# STM32H7S register map
File version: 1.4
CPU: CM7 r0p1, little endian, MPU, FPU, 4 interrupt priority bits
Registers are 32-bit, read-write, reset 0x0 unless marked. A register's access mark holds for its fields unless they carry their own. Offsets are from the block's base; [hi:lo] are bit positions; {n}, {i} and the like mark numbered series; 'fields as' and 'values as' point back to an identical list.

## ECC_DIAG_D1 — RAMECC1 configuration controller
Base 0x52009000
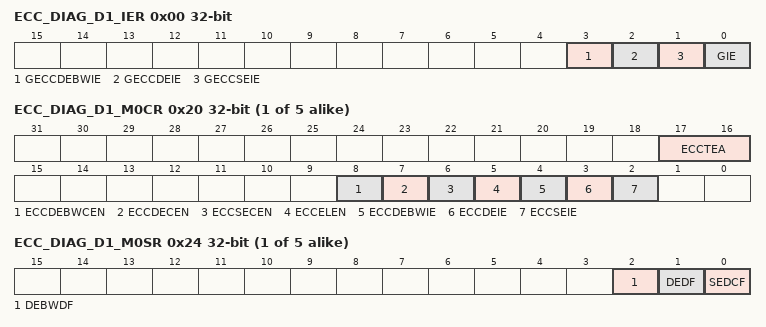
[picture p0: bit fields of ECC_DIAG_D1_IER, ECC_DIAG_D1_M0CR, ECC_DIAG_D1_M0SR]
0x00 ECC_DIAG_D1_IER — RAMECC interrupt enable register
  [3] GECCDEBWIE — Global ECC double error on byte write (BW) interrupt enable When GECCDEBWIE bit is set to 1, an interrupt is generated when an ECC double detection error occurs during a byte write operation to RAM (incomplete word write).
    0=no interrupt generated when an ECC double detection error occurs on byte write; 1=interrupt generated if an ECC double detection error occurs on byte write
  [2] GECCDEIE — Global ECC double error interrupt enable When GECCDEIE bit is set to 1, an interrupt is generated when an ECC double detection error occurs during a read operation from RAM.
    0=no interrupt generated when an ECC double detection error occurs; 1=interrupt generated if an ECC double detection error occurs
  [1] GECCSEIE — Global ECC single error interrupt enable When GECCSEIE bit is set to 1, an interrupt is generated when an ECC single error occurs during a read operation from RAM.
    0=no interrupt generated when an ECC single error occurs; 1=interrupt generated when an ECC single error occurs
  [0] GIE — Global interrupt enable When GIE bit is set to 1, an interrupt is generated when an enabled global ECC error (GECCDEBWIE, GECCDEIE or GECCSEIE) occurs.
    0=no interrupt generated when an ECC error occurs; 1=interrupt generated when an ECC error occurs
{0x20+0x20*i} ECC_DIAG_D1_M{i}CR (i=0..4) — RAMECC monitor {i} configuration register
  [17:16] ECCTEA — ECC Test ECC access
    0=inactive; 1=write and read access blocked on data memory; 2=write and read access blocked on ECC memory; 3=inactive
  [8] ECCDEBWCEN — ECC double error on byte write (BW) counter enable When ECCDEBWCEN bit is set to 1, the occurrence counter is incremented when an ECC double detection error occurs during a byte write operation to RAM.
    0=no counter increment when an ECC double detection error occurs on byte write; 1=counter increment when an ECC double detection error occurs on byte write
  [7] ECCDECEN — ECC double error counter enable When ECCDECEN bit is set to 1, the occurrence counter is incremented when an ECC double detection error occurs during a read operation from RAM.
    0=no counter increment when an ECC double detection error occurs; 1=counter increment when an ECC double detection error occurs
  [6] ECCSECEN — ECC single error counter enable When ECCSECEN bit is set to 1, the occurrence counter is incremented when an ECC single error occurs during a read operation from RAM.
    0=no counter increment when an ECC single error occurs; 1=counter increment when an ECC single error occurs
  [5] ECCELEN — ECC error latching enable When ECCELEN bit is set to 1, if an ECC error occurs (both for single error correction or double detection) during a read operation, the context (address, data and ECC code) that generated the error are latched to their respective registers.
    0=no error context preserved when an ECC error occurs; 1=error context preserved when an ECC error occurs
  [4] ECCDEBWIE — ECC double error on byte write (BW) interrupt enable When ECCDEBWIE bit is set to 1, monitor x generates an interrupt when an ECC double detection error occurs during a byte write operation to RAM.
    values as ECC_DIAG_D1_IER.GECCDEBWIE
  [3] ECCDEIE — ECC double error interrupt enable When ECCDEIE bit is set to 1, monitor x generates an interrupt when an ECC double detection error occurs during a read operation from RAM.
    values as ECC_DIAG_D1_IER.GECCDEIE
  [2] ECCSEIE — ECC single error interrupt enable When ECCSEIE bit is set to 1, monitor x generates an interrupt when an ECC single error occurs during a read operation from RAM.
    values as ECC_DIAG_D1_IER.GECCSEIE
{0x24+0x20*i} ECC_DIAG_D1_M{i}SR (i=0..4) — RAMECC monitor {i} status register
  [2] DEBWDF — ECC double error on byte write (BW) detected flag This bit is set by hardware. It is cleared by software by writing a 0
    0=no error detected; 1=error detected
  [1] DEDF — ECC double error detected flag This bit is set by hardware. It is cleared by software by writing a 0
    0=no error detected; 1=error detected
  [0] SEDCF — ECC single error detected and corrected flag This bit is set by hardware. It is cleared by software by writing a 0
    0=no error detected and corrected; 1=error detected and corrected
{0x28+0x20*i} ECC_DIAG_D1_M{i}FAR ro (i=0..4) — RAMECC monitor {i} failing address register
  [31:0] FADD — ECC error failing address When an ECC error occurs the FADD bit field contains the address that generated the ECC error.
{0x2C+0x20*i} ECC_DIAG_D1_M{i}FDRL ro (i=0..4) — RAMECC monitor {i} failing data low register
  [31:0] FDATAL — Failing data low When an ECC error occurs the FDATAL bit field contains the LSB part of the data that generated the error. For 32-bit word SRAM, this bit field contains the full memory word that generated the error.
{0x30+0x20*i} ECC_DIAG_D1_M{i}FDRH ro (i=0..4) — RAMECC monitor {i} failing data high register
  [31:0] FDATAH — Failing data high (64-bit memory) When an ECC error occurs the FDATAH bit field contains the MSB part of the data that generated the error.
{0x34+0x20*i} ECC_DIAG_D1_M{i}FECR ro (i=0..3) — RAMECC monitor {i} failing ECC error code register
  [31:0] FEC — Failing error code When an ECC error occurs the FEC bit field contains the ECC failing code that generated the error.
0xB4 RAMECC_M4FECR ro — RAMECC monitor 4 failing ECC error code register
  fields as ECC_DIAG_D1_M0FECR

## ECC_DIAG_D2 — RAMECC2 configuration controller
Base 0x58027000
Registers as ECC_DIAG_D1 (with ECC_DIAG_D1 read as ECC_DIAG_D2), without ECC_DIAG_D1_M0CR, ECC_DIAG_D1_M0SR, ECC_DIAG_D1_M0FAR, ECC_DIAG_D1_M0FDRL, ECC_DIAG_D1_M0FDRH, ECC_DIAG_D1_M0FECR, ECC_DIAG_D1_M{n}CR (n=2..4), ECC_DIAG_D1_M{n}SR (n=2..4), ECC_DIAG_D1_M{n}FAR (n=2..4), ECC_DIAG_D1_M{n}FDRL (n=2..4), ECC_DIAG_D1_M{n}FDRH (n=2..4), ECC_DIAG_D1_M2FECR, ECC_DIAG_D1_M3FECR, RAMECC_M4FECR.
